[part 1 of 4: packages /AUTOSAR_Platform/DataConstrs to /PATAC/MSM/ComponentTypes]
AUTOSAR XML (schema 4-0-3)
standard types defined: uint8, Boolean, UInt16, UInt32, UInt8
package /AUTOSAR_Platform/DataConstrs
  range DC_Boolean: raw 0..1
  range DC_UInt16: raw 0..65535
  range DC_UInt8: raw 0..255
package /DataTypes/Units
  unit NoUnit1: display-name=NoUnit, factor-si-to-unit=1, offset-si-to-unit=0
package /PATAC/MSM/ComponentTypes
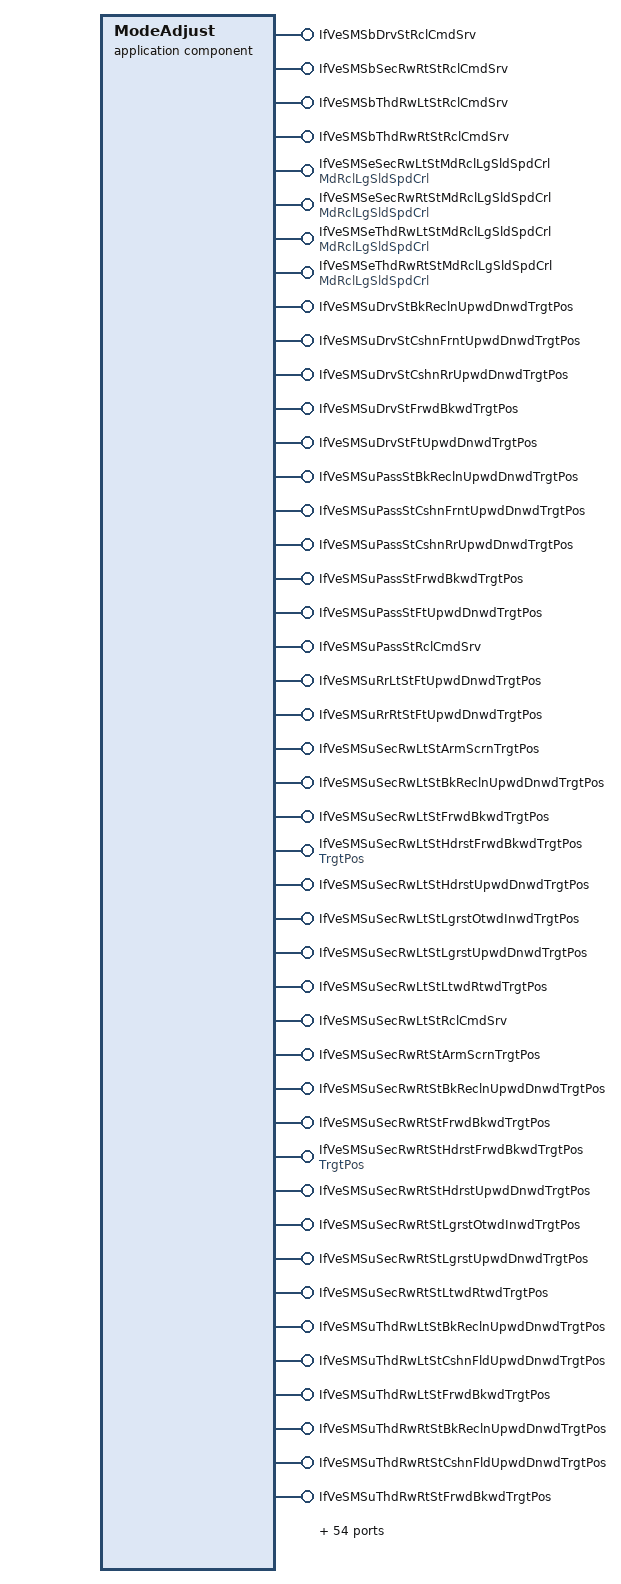
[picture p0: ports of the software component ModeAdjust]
  application sw component type ModeAdjust
    98 x provide port:
      IfVeSMSbDrvStRclCmdSrv: nonqueued-sender-com-spec{data-element=IfVeSMSbDrvStRclCmdSrv/Val, init-value=0}, provided-interface=IfVeSMSbDrvStRclCmdSrv
      IfVeSMSbSecRwRtStRclCmdSrv: nonqueued-sender-com-spec{data-element=IfVeSMSbSecRwRtStRclCmdSrv/Val, init-value=0}, provided-interface=IfVeSMSbSecRwRtStRclCmdSrv
      IfVeSMSbThdRwLtStRclCmdSrv: nonqueued-sender-com-spec{data-element=IfVeSMSbThdRwLtStRclCmdSrv/Val, init-value=0}, provided-interface=IfVeSMSbThdRwLtStRclCmdSrv
      IfVeSMSbThdRwRtStRclCmdSrv: nonqueued-sender-com-spec{data-element=IfVeSMSbThdRwRtStRclCmdSrv/Val, init-value=1}, provided-interface=IfVeSMSbThdRwRtStRclCmdSrv
      IfVeSMSeSecRwLtStMdRclLgSldSpdCrl: nonqueued-sender-com-spec{data-element=MdRclLgSldSpdCrl/Val, init-value=0}, provided-interface=MdRclLgSldSpdCrl
      IfVeSMSeSecRwRtStMdRclLgSldSpdCrl: nonqueued-sender-com-spec{data-element=MdRclLgSldSpdCrl/Val, init-value=0}, provided-interface=MdRclLgSldSpdCrl
      IfVeSMSeThdRwLtStMdRclLgSldSpdCrl: nonqueued-sender-com-spec{data-element=MdRclLgSldSpdCrl/Val, init-value=0}, provided-interface=MdRclLgSldSpdCrl
      IfVeSMSeThdRwRtStMdRclLgSldSpdCrl: nonqueued-sender-com-spec{data-element=MdRclLgSldSpdCrl/Val, init-value=0}, provided-interface=MdRclLgSldSpdCrl
      IfVeSMSuDrvStBkReclnUpwdDnwdTrgtPos: nonqueued-sender-com-spec{data-element=IfVeSMSuDrvStBkReclnUpwdDnwdTrgtPos/Val, init-value=4095}, provided-interface=IfVeSMSuDrvStBkReclnUpwdDnwdTrgtPos
      IfVeSMSuDrvStCshnFrntUpwdDnwdTrgtPos: nonqueued-sender-com-spec{data-element=IfVeSMSuDrvStCshnFrntUpwdDnwdTrgtPos/Val, init-value=4095}, provided-interface=IfVeSMSuDrvStCshnFrntUpwdDnwdTrgtPos
      IfVeSMSuDrvStCshnRrUpwdDnwdTrgtPos: nonqueued-sender-com-spec{data-element=IfVeSMSuDrvStCshnRrUpwdDnwdTrgtPos/Val, init-value=4095}, provided-interface=IfVeSMSuDrvStCshnRrUpwdDnwdTrgtPos
      IfVeSMSuDrvStFrwdBkwdTrgtPos: nonqueued-sender-com-spec{data-element=IfVeSMSuDrvStFrwdBkwdTrgtPos/Val, init-value=4095}, provided-interface=IfVeSMSuDrvStFrwdBkwdTrgtPos
      IfVeSMSuDrvStFtUpwdDnwdTrgtPos: nonqueued-sender-com-spec{data-element=IfVeSMSuDrvStFtUpwdDnwdTrgtPos/Val, init-value=4095}, provided-interface=IfVeSMSuDrvStFtUpwdDnwdTrgtPos
      IfVeSMSuPassStBkReclnUpwdDnwdTrgtPos: nonqueued-sender-com-spec{data-element=IfVeSMSuPassStBkReclnUpwdDnwdTrgtPos/Val, init-value=4095}, provided-interface=IfVeSMSuPassStBkReclnUpwdDnwdTrgtPos
      IfVeSMSuPassStCshnFrntUpwdDnwdTrgtPos: nonqueued-sender-com-spec{data-element=IfVeSMSuPassStCshnFrntUpwdDnwdTrgtPos/Val, init-value=4095}, provided-interface=IfVeSMSuPassStCshnFrntUpwdDnwdTrgtPos
      IfVeSMSuPassStCshnRrUpwdDnwdTrgtPos: nonqueued-sender-com-spec{data-element=IfVeSMSuPassStCshnRrUpwdDnwdTrgtPos/Val, init-value=4095}, provided-interface=IfVeSMSuPassStCshnRrUpwdDnwdTrgtPos
      IfVeSMSuPassStFrwdBkwdTrgtPos: nonqueued-sender-com-spec{data-element=IfVeSMSuPassStFrwdBkwdTrgtPos/Val, init-value=4095}, provided-interface=IfVeSMSuPassStFrwdBkwdTrgtPos
      IfVeSMSuPassStFtUpwdDnwdTrgtPos: nonqueued-sender-com-spec{data-element=IfVeSMSuPassStFtUpwdDnwdTrgtPos/Val, init-value=4095}, provided-interface=IfVeSMSuPassStFtUpwdDnwdTrgtPos
      IfVeSMSuPassStRclCmdSrv: nonqueued-sender-com-spec{data-element=IfVeSMSuPassStRclCmdSrv/Val, init-value=0}, provided-interface=IfVeSMSuPassStRclCmdSrv
      IfVeSMSuRrLtStFtUpwdDnwdTrgtPos: nonqueued-sender-com-spec{data-element=IfVeSMSuRrLtStFtUpwdDnwdTrgtPos/Val, init-value=0}, provided-interface=IfVeSMSuRrLtStFtUpwdDnwdTrgtPos
      IfVeSMSuRrRtStFtUpwdDnwdTrgtPos: nonqueued-sender-com-spec{data-element=IfVeSMSuRrRtStFtUpwdDnwdTrgtPos/Val, init-value=0}, provided-interface=IfVeSMSuRrRtStFtUpwdDnwdTrgtPos
      IfVeSMSuSecRwLtStArmScrnTrgtPos: nonqueued-sender-com-spec{data-element=IfVeSMSuSecRwLtStArmScrnTrgtPos/Val, init-value=4095}, provided-interface=IfVeSMSuSecRwLtStArmScrnTrgtPos
      IfVeSMSuSecRwLtStBkReclnUpwdDnwdTrgtPos: nonqueued-sender-com-spec{data-element=IfVeSMSuSecRwLtStBkReclnUpwdDnwdTrgtPos/Val, init-value=4095}, provided-interface=IfVeSMSuSecRwLtStBkReclnUpwdDnwdTrgtPos
      IfVeSMSuSecRwLtStFrwdBkwdTrgtPos: nonqueued-sender-com-spec{data-element=IfVeSMSuSecRwLtStFrwdBkwdTrgtPos/Val, init-value=4095}, provided-interface=IfVeSMSuSecRwLtStFrwdBkwdTrgtPos
      IfVeSMSuSecRwLtStHdrstFrwdBkwdTrgtPos: nonqueued-sender-com-spec{data-element=TrgtPos/Val, init-value=4095}, provided-interface=TrgtPos
      IfVeSMSuSecRwLtStHdrstUpwdDnwdTrgtPos: nonqueued-sender-com-spec{data-element=IfVeSMSuSecRwLtStHdrstUpwdDnwdTrgtPos/Val, init-value=4095}, provided-interface=IfVeSMSuSecRwLtStHdrstUpwdDnwdTrgtPos
      IfVeSMSuSecRwLtStLgrstOtwdInwdTrgtPos: nonqueued-sender-com-spec{data-element=IfVeSMSuSecRwLtStLgrstOtwdInwdTrgtPos/Val, init-value=0}, provided-interface=IfVeSMSuSecRwLtStLgrstOtwdInwdTrgtPos
      IfVeSMSuSecRwLtStLgrstUpwdDnwdTrgtPos: nonqueued-sender-com-spec{data-element=IfVeSMSuSecRwLtStLgrstUpwdDnwdTrgtPos/Val, init-value=4095}, provided-interface=IfVeSMSuSecRwLtStLgrstUpwdDnwdTrgtPos
      IfVeSMSuSecRwLtStLtwdRtwdTrgtPos: nonqueued-sender-com-spec{data-element=IfVeSMSuSecRwLtStLtwdRtwdTrgtPos/Val, init-value=4095}, provided-interface=IfVeSMSuSecRwLtStLtwdRtwdTrgtPos
      IfVeSMSuSecRwLtStRclCmdSrv: nonqueued-sender-com-spec{data-element=IfVeSMSuSecRwLtStRclCmdSrv/Val, init-value=0}, provided-interface=IfVeSMSuSecRwLtStRclCmdSrv
      IfVeSMSuSecRwRtStArmScrnTrgtPos: nonqueued-sender-com-spec{data-element=IfVeSMSuSecRwRtStArmScrnTrgtPos/Val, init-value=4095}, provided-interface=IfVeSMSuSecRwRtStArmScrnTrgtPos
      IfVeSMSuSecRwRtStBkReclnUpwdDnwdTrgtPos: nonqueued-sender-com-spec{data-element=IfVeSMSuSecRwRtStBkReclnUpwdDnwdTrgtPos/Val, init-value=4095}, provided-interface=IfVeSMSuSecRwRtStBkReclnUpwdDnwdTrgtPos
      IfVeSMSuSecRwRtStFrwdBkwdTrgtPos: nonqueued-sender-com-spec{data-element=IfVeSMSuSecRwRtStFrwdBkwdTrgtPos/Val, init-value=4095}, provided-interface=IfVeSMSuSecRwRtStFrwdBkwdTrgtPos
      IfVeSMSuSecRwRtStHdrstFrwdBkwdTrgtPos: nonqueued-sender-com-spec{data-element=TrgtPos/Val, init-value=4095}, provided-interface=TrgtPos
      IfVeSMSuSecRwRtStHdrstUpwdDnwdTrgtPos: nonqueued-sender-com-spec{data-element=IfVeSMSuSecRwRtStHdrstUpwdDnwdTrgtPos/Val, init-value=4095}, provided-interface=IfVeSMSuSecRwRtStHdrstUpwdDnwdTrgtPos
      IfVeSMSuSecRwRtStLgrstOtwdInwdTrgtPos: nonqueued-sender-com-spec{data-element=IfVeSMSuSecRwRtStLgrstOtwdInwdTrgtPos/Val, init-value=0}, provided-interface=IfVeSMSuSecRwRtStLgrstOtwdInwdTrgtPos
      IfVeSMSuSecRwRtStLgrstUpwdDnwdTrgtPos: nonqueued-sender-com-spec{data-element=IfVeSMSuSecRwRtStLgrstUpwdDnwdTrgtPos/Val, init-value=4095}, provided-interface=IfVeSMSuSecRwRtStLgrstUpwdDnwdTrgtPos
      IfVeSMSuSecRwRtStLtwdRtwdTrgtPos: nonqueued-sender-com-spec{data-element=IfVeSMSuSecRwRtStLtwdRtwdTrgtPos/Val, init-value=4095}, provided-interface=IfVeSMSuSecRwRtStLtwdRtwdTrgtPos
      IfVeSMSuThdRwLtStBkReclnUpwdDnwdTrgtPos: nonqueued-sender-com-spec{data-element=IfVeSMSuThdRwLtStBkReclnUpwdDnwdTrgtPos/Val, init-value=4095}, provided-interface=IfVeSMSuThdRwLtStBkReclnUpwdDnwdTrgtPos
      IfVeSMSuThdRwLtStCshnFldUpwdDnwdTrgtPos: nonqueued-sender-com-spec{data-element=IfVeSMSuThdRwLtStCshnFldUpwdDnwdTrgtPos/Val, init-value=4095}, provided-interface=IfVeSMSuThdRwLtStCshnFldUpwdDnwdTrgtPos
      IfVeSMSuThdRwLtStFrwdBkwdTrgtPos: nonqueued-sender-com-spec{data-element=IfVeSMSuThdRwLtStFrwdBkwdTrgtPos/Val, init-value=4095}, provided-interface=IfVeSMSuThdRwLtStFrwdBkwdTrgtPos
      IfVeSMSuThdRwRtStBkReclnUpwdDnwdTrgtPos: nonqueued-sender-com-spec{data-element=IfVeSMSuThdRwRtStBkReclnUpwdDnwdTrgtPos/Val, init-value=4095}, provided-interface=IfVeSMSuThdRwRtStBkReclnUpwdDnwdTrgtPos
      IfVeSMSuThdRwRtStCshnFldUpwdDnwdTrgtPos: nonqueued-sender-com-spec{data-element=IfVeSMSuThdRwRtStCshnFldUpwdDnwdTrgtPos/Val, init-value=4095}, provided-interface=IfVeSMSuThdRwRtStCshnFldUpwdDnwdTrgtPos
      IfVeSMSuThdRwRtStFrwdBkwdTrgtPos: nonqueued-sender-com-spec{data-element=IfVeSMSuThdRwRtStFrwdBkwdTrgtPos/Val, init-value=4095}, provided-interface=IfVeSMSuThdRwRtStFrwdBkwdTrgtPos
      isAcsMdEntryArrivedAtTargetPos: nonqueued-sender-com-spec{data-element=IsTargetPos/Val, init-value=0}, provided-interface=IsTargetPos
      isAcsMdEntryDoneFailed: nonqueued-sender-com-spec{data-element=DoneFailed/Val, init-value=0}, provided-interface=DoneFailed
      isAcsMdEntryDoneOK: nonqueued-sender-com-spec{data-element=DoneOK/Val, init-value=0}, provided-interface=DoneOK
      isAcsMdExtArrivedAtTargetPos: nonqueued-sender-com-spec{data-element=IsTargetPos/Val, init-value=0}, provided-interface=IsTargetPos
      isAcsMdExtDoneFailed: nonqueued-sender-com-spec{data-element=DoneFailed/Val, init-value=0}, provided-interface=DoneFailed
      isAcsMdExtDoneOK: nonqueued-sender-com-spec{data-element=DoneOK/Val, init-value=0}, provided-interface=DoneOK
      isINTMArrivedAtTargetPos: nonqueued-sender-com-spec{data-element=IsTargetPos/Val, init-value=0}, provided-interface=IsTargetPos
      isINTMDoneFailed: nonqueued-sender-com-spec{data-element=DoneFailed/Val, init-value=0}, provided-interface=DoneFailed
      isINTMDoneOK: nonqueued-sender-com-spec{data-element=DoneOK/Val, init-value=0}, provided-interface=DoneOK
      isINTMRArrivedAtTargetPos: nonqueued-sender-com-spec{data-element=IsTargetPos/Val, init-value=0}, provided-interface=IsTargetPos
      isINTMRDoneFailed: nonqueued-sender-com-spec{data-element=DoneFailed/Val, init-value=0}, provided-interface=DoneFailed
      isINTMRDoneOK: nonqueued-sender-com-spec{data-element=DoneOK/Val, init-value=0}, provided-interface=DoneOK
      isLfFamlyArrivedAtTargetPos: nonqueued-sender-com-spec{data-element=IsTargetPos/Val, init-value=0}, provided-interface=IsTargetPos
      isLfFamlyDoneFailed: nonqueued-sender-com-spec{data-element=DoneFailed/Val, init-value=0}, provided-interface=DoneFailed
      isLfFamlyDoneOK: nonqueued-sender-com-spec{data-element=DoneOK/Val, init-value=0}, provided-interface=DoneOK
      isLfLugArrivedAtTargetPos: nonqueued-sender-com-spec{data-element=IsTargetPos/Val, init-value=0}, provided-interface=IsTargetPos
      isLfLugDoneFailed: nonqueued-sender-com-spec{data-element=DoneFailed/Val, init-value=0}, provided-interface=DoneFailed
      isLfLugDoneOK: nonqueued-sender-com-spec{data-element=DoneOK/Val, init-value=0}, provided-interface=DoneOK
      isLfLyArrivedAtTargetPos: nonqueued-sender-com-spec{data-element=IsTargetPos/Val, init-value=0}, provided-interface=IsTargetPos
      isLfLyDoneFailed: nonqueued-sender-com-spec{data-element=DoneFailed/Val, init-value=0}, provided-interface=DoneFailed
      isLfLyDoneOK: nonqueued-sender-com-spec{data-element=DoneOK/Val, init-value=0}, provided-interface=DoneOK
      isLfRecoveryArrivedAtTargetPos: nonqueued-sender-com-spec{data-element=IsTargetPos/Val, init-value=0}, provided-interface=IsTargetPos
      isLfRecoveryDoneFailed: nonqueued-sender-com-spec{data-element=DoneFailed/Val, init-value=0}, provided-interface=DoneFailed
      isLfRecoveryDoneOK: nonqueued-sender-com-spec{data-element=DoneOK/Val, init-value=0}, provided-interface=DoneOK
      isLfVipArrivedAtTargetPos: nonqueued-sender-com-spec{data-element=IsTargetPos/Val, init-value=0}, provided-interface=IsTargetPos
      isLfVipDoneFailed: nonqueued-sender-com-spec{data-element=DoneFailed/Val, init-value=0}, provided-interface=DoneFailed
      isLfVipDoneOK: nonqueued-sender-com-spec{data-element=DoneOK/Val, init-value=0}, provided-interface=DoneOK
      isLgrstCloseLArrivedAtTargetPos: nonqueued-sender-com-spec{data-element=IsTargetPos/Val, init-value=0}, provided-interface=IsTargetPos
      isLgrstCloseLDoneFailed: nonqueued-sender-com-spec{data-element=DoneFailed/Val, init-value=0}, provided-interface=DoneFailed
      isLgrstCloseLDoneOK: nonqueued-sender-com-spec{data-element=DoneOK/Val, init-value=0}, provided-interface=DoneOK
      isLgrstCloseRArrivedAtTargetPos: nonqueued-sender-com-spec{data-element=IsTargetPos/Val, init-value=0}, provided-interface=IsTargetPos
      isLgrstCloseRDoneFailed: nonqueued-sender-com-spec{data-element=DoneFailed/Val, init-value=0}, provided-interface=DoneFailed
      isLgrstCloseRDoneOK: nonqueued-sender-com-spec{data-element=DoneOK/Val, init-value=0}, provided-interface=DoneOK
      isLgrstOpenLArrivedAtTargetPos: nonqueued-sender-com-spec{data-element=IsTargetPos/Val, init-value=0}, provided-interface=IsTargetPos
      isLgrstOpenLDoneFailed: nonqueued-sender-com-spec{data-element=DoneFailed/Val, init-value=0}, provided-interface=DoneFailed
      isLgrstOpenLDoneOK: nonqueued-sender-com-spec{data-element=DoneOK/Val, init-value=0}, provided-interface=DoneOK
      isLgrstOpenRArrivedAtTargetPos: nonqueued-sender-com-spec{data-element=IsTargetPos/Val, init-value=0}, provided-interface=IsTargetPos
      isLgrstOpenRDoneFailed: nonqueued-sender-com-spec{data-element=DoneFailed/Val, init-value=0}, provided-interface=DoneFailed
      isLgrstOpenRDoneOK: nonqueued-sender-com-spec{data-element=DoneOK/Val, init-value=0}, provided-interface=DoneOK
      isRfFamlyDoneFailed: nonqueued-sender-com-spec{data-element=DoneFailed/Val, init-value=0}, provided-interface=DoneFailed
      isRfFamlyDoneOK: nonqueued-sender-com-spec{data-element=DoneOK/Val, init-value=0}, provided-interface=DoneOK
      isRtFamlyArrivedAtTargetPos: nonqueued-sender-com-spec{data-element=IsTargetPos/Val, init-value=0}, provided-interface=IsTargetPos
      isRtLugArrivedAtTargetPos: nonqueued-sender-com-spec{data-element=IsTargetPos/Val, init-value=0}, provided-interface=IsTargetPos
      isRtLugDoneFailed: nonqueued-sender-com-spec{data-element=DoneFailed/Val, init-value=0}, provided-interface=DoneFailed
      isRtLugDoneOK: nonqueued-sender-com-spec{data-element=DoneOK/Val, init-value=0}, provided-interface=DoneOK
      isRtLyArrivedAtTargetPos: nonqueued-sender-com-spec{data-element=IsTargetPos/Val, init-value=0}, provided-interface=IsTargetPos
      isRtLyDoneFailed: nonqueued-sender-com-spec{data-element=DoneFailed/Val, init-value=0}, provided-interface=DoneFailed
      isRtLyDoneOK: nonqueued-sender-com-spec{data-element=DoneOK/Val, init-value=0}, provided-interface=DoneOK
      isRtRecoveryArrivedAtTargetPos: nonqueued-sender-com-spec{data-element=IsTargetPos/Val, init-value=0}, provided-interface=IsTargetPos
      isRtRecoveryDoneFailed: nonqueued-sender-com-spec{data-element=DoneFailed/Val, init-value=0}, provided-interface=DoneFailed
      isRtRecoveryDoneOK: nonqueued-sender-com-spec{data-element=DoneOK/Val, init-value=0}, provided-interface=DoneOK
      isRtVipArrivedAtTargetPos: nonqueued-sender-com-spec{data-element=IsTargetPos/Val, init-value=0}, provided-interface=IsTargetPos
      isRtVipDoneFailed: nonqueued-sender-com-spec{data-element=DoneFailed/Val, init-value=0}, provided-interface=DoneFailed
      isRtVipDoneOK: nonqueued-sender-com-spec{data-element=DoneOK/Val, init-value=0}, provided-interface=DoneOK
